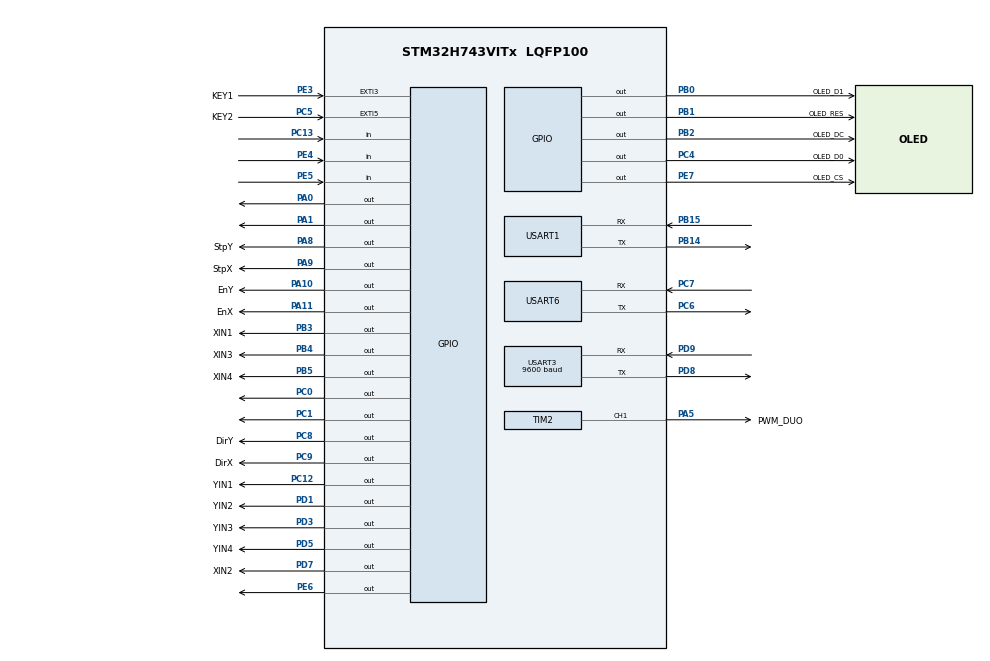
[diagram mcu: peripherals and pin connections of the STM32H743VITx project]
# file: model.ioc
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CORTEX_M7.AccessPermission-Cortex_Memory_Protection_Unit_Region0_Settings=MPU_REGION_FULL_ACCESS
CORTEX_M7.AccessPermission-Cortex_Memory_Protection_Unit_Region1_Settings=MPU_REGION_FULL_ACCESS
CORTEX_M7.AccessPermission-Cortex_Memory_Protection_Unit_Region2_Settings=MPU_REGION_FULL_ACCESS
CORTEX_M7.AccessPermission-Cortex_Memory_Protection_Unit_Region3_Settings=MPU_REGION_FULL_ACCESS
CORTEX_M7.AccessPermission-Cortex_Memory_Protection_Unit_Region4_Settings=MPU_REGION_FULL_ACCESS
CORTEX_M7.BaseAddress-Cortex_Memory_Protection_Unit_Region0_Settings=0x24000000
CORTEX_M7.BaseAddress-Cortex_Memory_Protection_Unit_Region1_Settings=0x30000000
CORTEX_M7.BaseAddress-Cortex_Memory_Protection_Unit_Region2_Settings=0x30020000
CORTEX_M7.BaseAddress-Cortex_Memory_Protection_Unit_Region3_Settings=0x30040000
CORTEX_M7.BaseAddress-Cortex_Memory_Protection_Unit_Region4_Settings=0x38000000
CORTEX_M7.CPU_DCache=Enabled
CORTEX_M7.CPU_ICache=Enabled
CORTEX_M7.Enable-Cortex_Memory_Protection_Unit_Region0_Settings=MPU_REGION_ENABLE
CORTEX_M7.Enable-Cortex_Memory_Protection_Unit_Region1_Settings=MPU_REGION_ENABLE
CORTEX_M7.Enable-Cortex_Memory_Protection_Unit_Region2_Settings=MPU_REGION_ENABLE
CORTEX_M7.Enable-Cortex_Memory_Protection_Unit_Region3_Settings=MPU_REGION_ENABLE
CORTEX_M7.Enable-Cortex_Memory_Protection_Unit_Region4_Settings=MPU_REGION_ENABLE
CORTEX_M7.IsBufferable-Cortex_Memory_Protection_Unit_Region0_Settings=MPU_ACCESS_BUFFERABLE
CORTEX_M7.IsCacheable-Cortex_Memory_Protection_Unit_Region0_Settings=MPU_ACCESS_CACHEABLE
CORTEX_M7.MPU_Control=MPU_PRIVILEGED_DEFAULT
CORTEX_M7.Size-Cortex_Memory_Protection_Unit_Region0_Settings=MPU_REGION_SIZE_512KB
CORTEX_M7.Size-Cortex_Memory_Protection_Unit_Region1_Settings=MPU_REGION_SIZE_128KB
CORTEX_M7.Size-Cortex_Memory_Protection_Unit_Region2_Settings=MPU_REGION_SIZE_128KB
CORTEX_M7.Size-Cortex_Memory_Protection_Unit_Region3_Settings=MPU_REGION_SIZE_32KB
CORTEX_M7.Size-Cortex_Memory_Protection_Unit_Region4_Settings=MPU_REGION_SIZE_64KB
CORTEX_M7.TypeExtField-Cortex_Memory_Protection_Unit_Region0_Settings=MPU_TEX_LEVEL1
CORTEX_M7.TypeExtField-Cortex_Memory_Protection_Unit_Region1_Settings=MPU_TEX_LEVEL1
CORTEX_M7.TypeExtField-Cortex_Memory_Protection_Unit_Region2_Settings=MPU_TEX_LEVEL1
CORTEX_M7.TypeExtField-Cortex_Memory_Protection_Unit_Region3_Settings=MPU_TEX_LEVEL1
CORTEX_M7.TypeExtField-Cortex_Memory_Protection_Unit_Region4_Settings=MPU_TEX_LEVEL1
Dma.Request0=USART3_RX
Dma.USART3_RX.0.Direction=DMA_PERIPH_TO_MEMORY
Dma.USART3_RX.0.EventEnable=DISABLE
Dma.USART3_RX.0.FIFOMode=DMA_FIFOMODE_DISABLE
Dma.USART3_RX.0.Instance=DMA1_Stream0
Dma.USART3_RX.0.MemDataAlignment=DMA_MDATAALIGN_BYTE
Dma.USART3_RX.0.MemInc=DMA_MINC_ENABLE
Dma.USART3_RX.0.Mode=DMA_NORMAL
Dma.USART3_RX.0.PeriphDataAlignment=DMA_PDATAALIGN_BYTE
Dma.USART3_RX.0.PeriphInc=DMA_PINC_DISABLE
Dma.USART3_RX.0.Polarity=HAL_DMAMUX_REQ_GEN_RISING
Dma.USART3_RX.0.Priority=DMA_PRIORITY_LOW
Dma.USART3_RX.0.RequestNumber=1
Dma.USART3_RX.0.SignalID=NONE
Dma.USART3_RX.0.SyncEnable=DISABLE
Dma.USART3_RX.0.SyncPolarity=HAL_DMAMUX_SYNC_NO_EVENT
Dma.USART3_RX.0.SyncRequestNumber=1
Dma.USART3_RX.0.SyncSignalID=NONE
Mcu.Family=STM32H7
Mcu.Name=STM32H743VITx
Mcu.Package=LQFP100
NVIC.DMA1_Stream0_IRQn=true\:0\:0\:false\:false\:true\:false\:true\:true
NVIC.PriorityGroup=NVIC_PRIORITYGROUP_4
NVIC.TIM15_IRQn=true\:5\:0\:true\:false\:true\:true\:true\:true
NVIC.TIM16_IRQn=true\:6\:0\:true\:false\:true\:true\:true\:true
NVIC.TIM17_IRQn=true\:4\:0\:true\:false\:true\:true\:true\:true
NVIC.USART1_IRQn=true\:3\:0\:true\:false\:true\:true\:true\:true
NVIC.USART3_IRQn=true\:2\:0\:true\:false\:true\:true\:true\:true
PA0.Signal=GPIO_Output
PA1.Signal=GPIO_Output
PA10.GPIO_Label=EnY
PA10.GPIO_ModeDefaultOutputPP=GPIO_MODE_OUTPUT_PP
PA10.GPIO_PuPd=GPIO_PULLUP
PA10.GPIO_Speed=GPIO_SPEED_FREQ_HIGH
PA10.PinState=GPIO_PIN_SET
PA10.Signal=GPIO_Output
PA11.GPIO_Label=EnX
PA11.GPIO_ModeDefaultOutputPP=GPIO_MODE_OUTPUT_PP
PA11.GPIO_PuPd=GPIO_PULLUP
PA11.GPIO_Speed=GPIO_SPEED_FREQ_HIGH
PA11.PinState=GPIO_PIN_SET
PA11.Signal=GPIO_Output
PA13\ (JTMS/SWDIO).Mode=Serial_Wire
PA13\ (JTMS/SWDIO).Signal=DEBUG_JTMS-SWDIO
PA14\ (JTCK/SWCLK).Mode=Serial_Wire
PA14\ (JTCK/SWCLK).Signal=DEBUG_JTCK-SWCLK
PA5.GPIO_Label=PWM_DUO
PA5.Signal=S_TIM2_CH1_ETR
PA8.GPIO_Label=StpY
PA8.GPIO_ModeDefaultOutputPP=GPIO_MODE_OUTPUT_PP
PA8.GPIO_PuPd=GPIO_PULLDOWN
PA8.GPIO_Speed=GPIO_SPEED_FREQ_HIGH
PA8.PinState=GPIO_PIN_RESET
PA8.Signal=GPIO_Output
PA9.GPIO_Label=StpX
PA9.GPIO_ModeDefaultOutputPP=GPIO_MODE_OUTPUT_PP
PA9.GPIO_PuPd=GPIO_PULLDOWN
PA9.GPIO_Speed=GPIO_SPEED_FREQ_HIGH
PA9.PinState=GPIO_PIN_RESET
PA9.Signal=GPIO_Output
PB0.GPIO_Label=OLED_D1
PB0.GPIO_PuPd=GPIO_PULLUP
PB0.Signal=GPIO_Output
PB1.GPIO_Label=OLED_RES
PB1.GPIO_PuPd=GPIO_PULLUP
PB1.Signal=GPIO_Output
PB14.Mode=Asynchronous
PB14.Signal=USART1_TX
PB15.Mode=Asynchronous
PB15.Signal=USART1_RX
PB2.GPIO_Label=OLED_DC
PB2.GPIO_PuPd=GPIO_PULLUP
PB2.Signal=GPIO_Output
PB3\ (JTDO/TRACESWO).GPIO_Label=XIN1
PB3\ (JTDO/TRACESWO).GPIO_ModeDefaultOutputPP=GPIO_MODE_OUTPUT_PP
PB3\ (JTDO/TRACESWO).GPIO_PuPd=GPIO_PULLDOWN
PB3\ (JTDO/TRACESWO).GPIO_Speed=GPIO_SPEED_FREQ_HIGH
PB3\ (JTDO/TRACESWO).PinState=GPIO_PIN_RESET
PB3\ (JTDO/TRACESWO).Signal=GPIO_Output
PB4\ (NJTRST).GPIO_Label=XIN3
PB4\ (NJTRST).GPIO_ModeDefaultOutputPP=GPIO_MODE_OUTPUT_PP
PB4\ (NJTRST).GPIO_PuPd=GPIO_PULLDOWN
PB4\ (NJTRST).GPIO_Speed=GPIO_SPEED_FREQ_HIGH
PB4\ (NJTRST).PinState=GPIO_PIN_RESET
PB4\ (NJTRST).Signal=GPIO_Output
PB5.GPIO_Label=XIN4
PB5.GPIO_ModeDefaultOutputPP=GPIO_MODE_OUTPUT_PP
PB5.GPIO_PuPd=GPIO_PULLDOWN
PB5.GPIO_Speed=GPIO_SPEED_FREQ_HIGH
PB5.PinState=GPIO_PIN_RESET
PB5.Signal=GPIO_Output
PC0.Signal=GPIO_Output
PC1.Signal=GPIO_Output
PC12.GPIO_Label=YIN1
PC12.Signal=GPIO_Output
PC13.Signal=GPIO_Input
PC4.GPIO_Label=OLED_D0
PC4.GPIO_PuPd=GPIO_PULLUP
PC4.Signal=GPIO_Output
PC5.GPIO_Label=KEY2
PC5.GPIO_PuPd=GPIO_PULLUP
PC5.Signal=GPXTI5
PC6.Mode=Asynchronous
PC6.Signal=USART6_TX
PC7.Mode=Asynchronous
PC7.Signal=USART6_RX
PC8.GPIO_Label=DirY
PC8.GPIO_ModeDefaultOutputPP=GPIO_MODE_OUTPUT_PP
PC8.GPIO_PuPd=GPIO_PULLDOWN
PC8.GPIO_Speed=GPIO_SPEED_FREQ_HIGH
PC8.PinState=GPIO_PIN_RESET
PC8.Signal=GPIO_Output
PC9.GPIO_Label=DirX
PC9.GPIO_ModeDefaultOutputPP=GPIO_MODE_OUTPUT_PP
PC9.GPIO_PuPd=GPIO_PULLDOWN
PC9.GPIO_Speed=GPIO_SPEED_FREQ_HIGH
PC9.PinState=GPIO_PIN_RESET
PC9.Signal=GPIO_Output
PD1.GPIO_Label=YIN2
PD1.GPIO_ModeDefaultOutputPP=GPIO_MODE_OUTPUT_PP
PD1.GPIO_PuPd=GPIO_PULLDOWN
PD1.GPIO_Speed=GPIO_SPEED_FREQ_HIGH
PD1.PinState=GPIO_PIN_RESET
PD1.Signal=GPIO_Output
PD3.GPIO_Label=YIN3
PD3.GPIO_ModeDefaultOutputPP=GPIO_MODE_OUTPUT_PP
PD3.GPIO_PuPd=GPIO_PULLDOWN
PD3.GPIO_Speed=GPIO_SPEED_FREQ_HIGH
PD3.PinState=GPIO_PIN_RESET
PD3.Signal=GPIO_Output
PD5.GPIO_Label=YIN4
PD5.Signal=GPIO_Output
PD7.GPIO_Label=XIN2
PD7.GPIO_ModeDefaultOutputPP=GPIO_MODE_OUTPUT_PP
PD7.GPIO_PuPd=GPIO_PULLDOWN
PD7.GPIO_Speed=GPIO_SPEED_FREQ_HIGH
PD7.PinState=GPIO_PIN_RESET
PD7.Signal=GPIO_Output
PD8.Mode=Asynchronous
PD8.Signal=USART3_TX
PD9.Mode=Asynchronous
PD9.Signal=USART3_RX
PE3.GPIO_Label=KEY1
PE3.GPIO_PuPd=GPIO_PULLUP
PE3.Signal=GPXTI3
PE4.Signal=GPIO_Input
PE5.Signal=GPIO_Input
PE6.Signal=GPIO_Output
PE7.GPIO_Label=OLED_CS
PE7.GPIO_PuPd=GPIO_PULLUP
PE7.Signal=GPIO_Output
PH0-OSC_IN\ (PH0).Mode=HSE-External-Oscillator
PH0-OSC_IN\ (PH0).Signal=RCC_OSC_IN
PH1-OSC_OUT\ (PH1).Mode=HSE-External-Oscillator
PH1-OSC_OUT\ (PH1).Signal=RCC_OSC_OUT
ProjectManager.HeapSize=0x200
ProjectManager.StackSize=0x7400
ProjectManager.TargetToolchain=MDK-ARM V5.32
RCC.ADCFreq_Value=50390625
RCC.APB1Freq_Value=120000000
RCC.APB2Freq_Value=120000000
RCC.APB3Freq_Value=120000000
RCC.APB4Freq_Value=120000000
RCC.CortexFreq_Value=480000000
RCC.D1PPRE=RCC_APB3_DIV2
RCC.D2PPRE1=RCC_APB1_DIV2
RCC.D2PPRE2=RCC_APB2_DIV2
RCC.D3PPRE=RCC_APB4_DIV2
RCC.DIVM1=5
RCC.DIVN1=192
RCC.HCLKFreq_Value=240000000
RCC.HPRE=RCC_HCLK_DIV2
RCC.HSE_VALUE=25000000
RCC.PLL2FRACN=0
RCC.PLLFRACN=0
RCC.PLLSourceVirtual=RCC_PLLSOURCE_HSE
RCC.PWR_Regulator_Voltage_Scale=PWR_REGULATOR_VOLTAGE_SCALE0
RCC.ProductRev=revV
RCC.SYSCLKFreq_VALUE=480000000
RCC.SYSCLKSource=RCC_SYSCLKSOURCE_PLLCLK
RCC.USBFreq_Value=480000000
SH.S_TIM2_CH1_ETR.0=TIM2_CH1,PWM Generation1 CH1
TIM15.Period=3000-1
TIM15.Prescaler=240-1
TIM16.Period=3000-1
TIM16.Prescaler=240-1
TIM17.Period=3000-1
TIM17.Prescaler=240-1
TIM2.Channel-PWM\ Generation1\ CH1=TIM_CHANNEL_1
TIM7.Prescaler=239
USART1.VirtualMode-Asynchronous=VM_ASYNC
USART3.BaudRate=9600
USART3.VirtualMode-Asynchronous=VM_ASYNC
USART6.VirtualMode=VM_ASYNC
VP_TIM15_VS_ClockSourceINT.Mode=Internal
VP_TIM16_VS_ClockSourceINT.Mode=Enable_Timer
VP_TIM17_VS_ClockSourceINT.Mode=Enable_Timer
VP_TIM2_VS_ClockSourceINT.Mode=Internal
VP_TIM3_VS_ClockSourceINT.Mode=Internal
VP_TIM7_VS_ClockSourceINT.Mode=Enable_Timer
board=custom

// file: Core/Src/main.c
/* USER CODE BEGIN Header */
/**
  ******************************************************************************
  * @file           : main.c
  * @brief          : Main program body
	******************************************************************************
	* @attention
	*
	* Copyright (c) 2025 STMicroelectronics.
	* All rights reserved.
  *
  * This software is licensed under terms that can be found in the LICENSE file
  * in the root directory of this software component.
  * If no LICENSE file comes with this software, it is provided AS-IS.
  *
  ******************************************************************************
  */
/* USER CODE END Header */
#include "main.h"
#include "dma.h"
#include "tim.h"
#include "usart.h"
#include "gpio.h"

void SystemClock_Config(void);
static void MPU_Initialize(void);
static void MPU_Config(void);

int main(void)
{

  /* Enable I-Cache---------------------------------------------------------*/
  SCB_EnableICache();

  /* Enable D-Cache---------------------------------------------------------*/
  SCB_EnableDCache();

  /* MCU Configuration--------------------------------------------------------*/

  /* Reset of all peripherals, Initializes the Flash interface and the Systick. */
  HAL_Init();

  /* MPU Configuration--------------------------------------------------------*/
  MPU_Config();

  /* Configure the system clock */
  SystemClock_Config();

  /* Initialize all configured peripherals */
  MX_GPIO_Init();
  MX_DMA_Init();
  MX_USART3_UART_Init();
  MX_USART6_UART_Init();
  MX_TIM3_Init();
  MX_TIM2_Init();
  MX_TIM16_Init();
  MX_TIM17_Init();
  MX_TIM7_Init();
  MX_USART1_UART_Init();
  MX_TIM15_Init();
  /* USER CODE BEGIN 2 */

  OLED_Init();
  OLED_ShowString(0, 0, "Hello,World!", 8, 1);
  OLED_Refresh();
  char msg[20] = {0};

  int16_t receive_x = 0;
  int16_t receive_y = 0;
  //HAL_UART_Receive_DMA(&huart3, msg, 4);

  /* USER CODE END 2 */

  /* Infinite loop */
  /* USER CODE BEGIN WHILE */
  while (1)
  {
    Step42_speedMode_uart(0, 1, 5);
    HAL_Delay(3000);
    Step42_speedMode_uart(0, 0, 1);
    HAL_Delay(3000);
    /* USER CODE END WHILE */

  }
}

void SystemClock_Config(void)
{
  RCC_OscInitTypeDef RCC_OscInitStruct = {0};
  RCC_ClkInitTypeDef RCC_ClkInitStruct = {0};

  /** Supply configuration update enable
  */
  HAL_PWREx_ConfigSupply(PWR_LDO_SUPPLY);

  /** Configure the main internal regulator output voltage
  */
  __HAL_PWR_VOLTAGESCALING_CONFIG(PWR_REGULATOR_VOLTAGE_SCALE1);

  while(!__HAL_PWR_GET_FLAG(PWR_FLAG_VOSRDY)) {}

  __HAL_RCC_SYSCFG_CLK_ENABLE();
  __HAL_PWR_VOLTAGESCALING_CONFIG(PWR_REGULATOR_VOLTAGE_SCALE0);

  while(!__HAL_PWR_GET_FLAG(PWR_FLAG_VOSRDY)) {}

  /** Initializes the RCC Oscillators according to the specified parameters
  * in the RCC_OscInitTypeDef structure.
  */
  RCC_OscInitStruct.OscillatorType = RCC_OSCILLATORTYPE_HSE;
  RCC_OscInitStruct.HSEState = RCC_HSE_ON;
  RCC_OscInitStruct.PLL.PLLState = RCC_PLL_ON;
  RCC_OscInitStruct.PLL.PLLSource = RCC_PLLSOURCE_HSE;
  RCC_OscInitStruct.PLL.PLLM = 5;
  RCC_OscInitStruct.PLL.PLLN = 192;
  RCC_OscInitStruct.PLL.PLLP = 2;
  RCC_OscInitStruct.PLL.PLLQ = 2;
  RCC_OscInitStruct.PLL.PLLR = 2;
  RCC_OscInitStruct.PLL.PLLRGE = RCC_PLL1VCIRANGE_2;
  RCC_OscInitStruct.PLL.PLLVCOSEL = RCC_PLL1VCOWIDE;
  RCC_OscInitStruct.PLL.PLLFRACN = 0;
  if (HAL_RCC_OscConfig(&RCC_OscInitStruct) != HAL_OK)
  {
    Error_Handler();
  }

  /** Initializes the CPU, AHB and APB buses clocks
  */
  RCC_ClkInitStruct.ClockType = RCC_CLOCKTYPE_HCLK|RCC_CLOCKTYPE_SYSCLK
                              |RCC_CLOCKTYPE_PCLK1|RCC_CLOCKTYPE_PCLK2
                              |RCC_CLOCKTYPE_D3PCLK1|RCC_CLOCKTYPE_D1PCLK1;
  RCC_ClkInitStruct.SYSCLKSource = RCC_SYSCLKSOURCE_PLLCLK;
  RCC_ClkInitStruct.SYSCLKDivider = RCC_SYSCLK_DIV1;
  RCC_ClkInitStruct.AHBCLKDivider = RCC_HCLK_DIV2;
  RCC_ClkInitStruct.APB3CLKDivider = RCC_APB3_DIV2;
  RCC_ClkInitStruct.APB1CLKDivider = RCC_APB1_DIV2;
  RCC_ClkInitStruct.APB2CLKDivider = RCC_APB2_DIV2;
  RCC_ClkInitStruct.APB4CLKDivider = RCC_APB4_DIV2;

  if (HAL_RCC_ClockConfig(&RCC_ClkInitStruct, FLASH_LATENCY_4) != HAL_OK)
  {
    Error_Handler();
  }
}

/* MPU Configuration */

void MPU_Config(void)
{
  MPU_Region_InitTypeDef MPU_InitStruct = {0};

  /* Disables the MPU */
  HAL_MPU_Disable();

  /** Initializes and configures the Region and the memory to be protected
  */
  MPU_InitStruct.Enable = MPU_REGION_ENABLE;
  MPU_InitStruct.Number = MPU_REGION_NUMBER0;
  MPU_InitStruct.BaseAddress = 0x24000000;
  MPU_InitStruct.Size = MPU_REGION_SIZE_512KB;
  MPU_InitStruct.SubRegionDisable = 0x0;
  MPU_InitStruct.TypeExtField = MPU_TEX_LEVEL1;
  MPU_InitStruct.AccessPermission = MPU_REGION_FULL_ACCESS;
  MPU_InitStruct.DisableExec = MPU_INSTRUCTION_ACCESS_ENABLE;
  MPU_InitStruct.IsShareable = MPU_ACCESS_NOT_SHAREABLE;
  MPU_InitStruct.IsCacheable = MPU_ACCESS_CACHEABLE;
  MPU_InitStruct.IsBufferable = MPU_ACCESS_BUFFERABLE;

  HAL_MPU_ConfigRegion(&MPU_InitStruct);

  /** Initializes and configures the Region and the memory to be protected
  */
  MPU_InitStruct.Number = MPU_REGION_NUMBER1;
  MPU_InitStruct.BaseAddress = 0x30000000;
  MPU_InitStruct.Size = MPU_REGION_SIZE_128KB;
  MPU_InitStruct.IsCacheable = MPU_ACCESS_NOT_CACHEABLE;
  MPU_InitStruct.IsBufferable = MPU_ACCESS_NOT_BUFFERABLE;

  HAL_MPU_ConfigRegion(&MPU_InitStruct);

  /** Initializes and configures the Region and the memory to be protected
  */
  MPU_InitStruct.Number = MPU_REGION_NUMBER2;
  MPU_InitStruct.BaseAddress = 0x30020000;

  HAL_MPU_ConfigRegion(&MPU_InitStruct);

  /** Initializes and configures the Region and the memory to be protected
  */
  MPU_InitStruct.Number = MPU_REGION_NUMBER3;
  MPU_InitStruct.BaseAddress = 0x30040000;
  MPU_InitStruct.Size = MPU_REGION_SIZE_32KB;

  HAL_MPU_ConfigRegion(&MPU_InitStruct);

  /** Initializes and configures the Region and the memory to be protected
  */
  MPU_InitStruct.Number = MPU_REGION_NUMBER4;
  MPU_InitStruct.BaseAddress = 0x38000000;
  MPU_InitStruct.Size = MPU_REGION_SIZE_64KB;

  HAL_MPU_ConfigRegion(&MPU_InitStruct);
  /* Enables the MPU */
  HAL_MPU_Enable(MPU_PRIVILEGED_DEFAULT);

}

void Error_Handler(void)
{
  __disable_irq();
  while (1)
  {
  }
}
